# esp8266 register map
File version: 1.0
CPU: Xtensa LX106 1, little endian, no MPU, FPU, 3 interrupt priority bits
Registers are 32-bit, read-write, reset 0x0 unless marked. A register's access mark holds for its fields unless they carry their own. Offsets are from the block's base; [hi:lo] are bit positions; {n}, {i} and the like mark numbered series.

## SPI0
Base 0x60000200
Same registers: SPI1 0x60000100
0x00 SPI_CMD — In the master mode, it is the start bit of a single operation. Self-clear by hardware
  [18] spi_usr
0x04 SPI_ADDR — In the master mode, it is the value of address in "address" phase.
  [31:0] iodata_start_addr
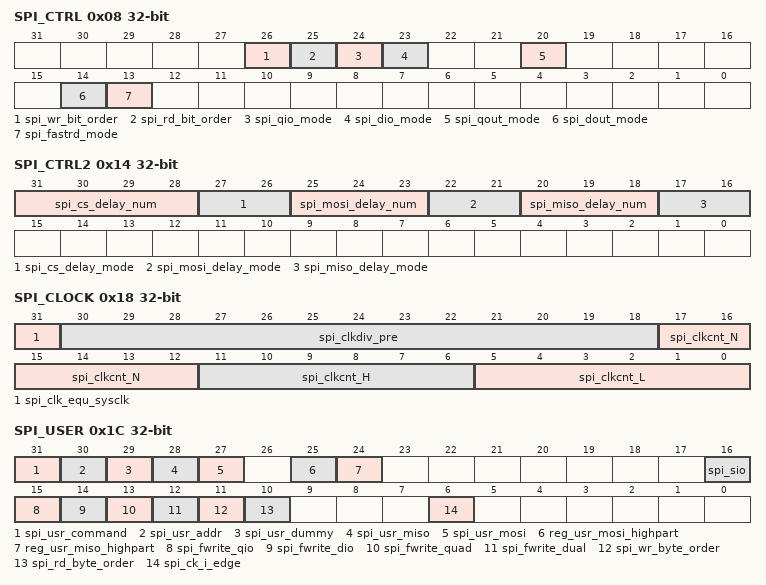
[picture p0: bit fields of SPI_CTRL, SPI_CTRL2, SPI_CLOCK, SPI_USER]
0x08 SPI_CTRL
  [26] spi_wr_bit_order — In "command", "address", "write-data" (MOSI) phases, 1: LSB first; 0: MSB first
  [25] spi_rd_bit_order — In "read-data" (MISO) phase, 1: LSB first; 0: MSB first
  [24] spi_qio_mode — In the read operations, "address" phase and "read-data" phase apply 4 signals
  [23] spi_dio_mode — In the read operations, "address" phase and "read-data" phase apply 2 signals
  [20] spi_qout_mode — In the read operations, "read-data" phase apply 4 signals
  [14] spi_dout_mode — In the read operations, "read-data" phase apply 2 signals
  [13] spi_fastrd_mode — this bit enable the bits: spi_qio_mode, spi_dio_mode, spi_qout_mode and spi_dout_mode
0x10 SPI_RD_STATUS — In the slave mode, this register are the status register for the master to read out.
  [31:0] slv_rd_status
0x14 SPI_CTRL2 — spi_cs signal is delayed by 80MHz clock cycles
  [31:28] spi_cs_delay_num — spi_cs signal is delayed by 80MHz clock cycles
  [27:26] spi_cs_delay_mode — spi_cs signal is delayed by spi_clk. 0: zero; 1: half cycle; 2: one cycle
  [25:23] spi_mosi_delay_num — MOSI signals are delayed by 80MHz clock cycles
  [22:21] spi_mosi_delay_mode — MOSI signals are delayed by spi_clk. 0: zero; 1: half cycle; 2: one cycle
  [20:18] spi_miso_delay_num — MISO signals are delayed by 80MHz clock cycles
  [17:16] spi_miso_delay_mode — MISO signals are delayed by spi_clk. 0: zero; 1: half cycle; 2: one cycle
0x18 SPI_CLOCK — In the master mode, 1: spi_clk is eqaul to 80MHz, 0: spi_clk is divided from 80 MHz clock.
  [31] spi_clk_equ_sysclk — In the master mode, 1: spi_clk is eqaul to 80MHz, 0: spi_clk is divided from 80 MHz clock.
  [30:18] spi_clkdiv_pre — In the master mode, it is pre-divider of spi_clk.
  [17:12] spi_clkcnt_N — In the master mode, it is the divider of spi_clk. So spi_clk frequency is 80MHz/(spi_clkdiv_pre+1)/(spi_clkcnt_N+1)
  [11:6] spi_clkcnt_H — In the master mode, it must be floor((spi_clkcnt_N+1)/2-1). In the slave mode, it must be 0.
  [5:0] spi_clkcnt_L — In the master mode, it must be eqaul to spi_clkcnt_N. In the slave mode, it must be 0.
0x1C SPI_USER — This bit enable the "command" phase of an operation.
  [31] spi_usr_command — This bit enable the "command" phase of an operation.
  [30] spi_usr_addr — This bit enable the "address" phase of an operation.
  [29] spi_usr_dummy — This bit enable the "dummy" phase of an operation.
  [28] spi_usr_miso — This bit enable the "read-data" phase of an operation.
  [27] spi_usr_mosi — This bit enable the "write-data" phase of an operation.
  [25] reg_usr_mosi_highpart — 1: "write-data" phase only access to high-part of the buffer spi_w8~spi_w15
  [24] reg_usr_miso_highpart — 1: "read-data" phase only access to high-part of the buffer spi_w8~spi_w15
  [16] spi_sio — 1: mosi and miso signals share the same pin
  [15] spi_fwrite_qio — In the write operations, "address" phase and "read-data" phase apply 4 signals
  [14] spi_fwrite_dio — In the write operations, "address" phase and "read-data" phase apply 2 signals
  [13] spi_fwrite_quad — In the write operations, "read-data" phase apply 4 signals
  [12] spi_fwrite_dual — In the write operations, "read-data" phase apply 2 signals
  [11] spi_wr_byte_order — In "command", "address", "write-data" (MOSI) phases, 1: little-endian; 0: big_endian
  [10] spi_rd_byte_order — In "read-data" (MISO) phase, 1: little-endian; 0: big_endian
  [6] spi_ck_i_edge — In the slave mode, 1: rising-edge; 0: falling-edge
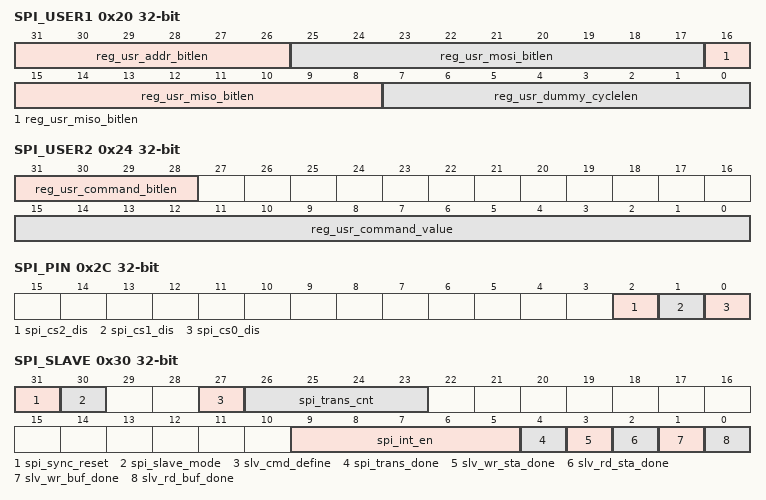
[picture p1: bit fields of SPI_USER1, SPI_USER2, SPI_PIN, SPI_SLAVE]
0x20 SPI_USER1 — The length in bits of "address" phase. The register value shall be (bit_num-1)
  [31:26] reg_usr_addr_bitlen — The length in bits of "address" phase. The register value shall be (bit_num-1)
  [25:17] reg_usr_mosi_bitlen — The length in bits of "write-data" phase. The register value shall be (bit_num-1)
  [16:8] reg_usr_miso_bitlen — The length in bits of "read-data" phase. The register value shall be (bit_num-1)
  [7:0] reg_usr_dummy_cyclelen — The length in spi_clk cycles of "dummy" phase. The register value shall be (cycle_num-1)
0x24 SPI_USER2 — The length in bits of "command" phase. The register value shall be (bit_num-1)
  [31:28] reg_usr_command_bitlen — The length in bits of "command" phase. The register value shall be (bit_num-1)
  [15:0] reg_usr_command_value — The value of "command" phase
0x28 SPI_WR_STATUS — In the slave mode, this register are the status register for the master to write into.
  [31:0] slv_wr_status
0x2C SPI_PIN — 1: disable CS2; 0: spi_cs signal is from/to CS2 pin
  [2] spi_cs2_dis — 1: disable CS2; 0: spi_cs signal is from/to CS2 pin
  [1] spi_cs1_dis — 1: disable CS1; 0: spi_cs signal is from/to CS1 pin
  [0] spi_cs0_dis — 1: disable CS0; 0: spi_cs signal is from/to CS0 pin
0x30 SPI_SLAVE access per field — It is the synchronous reset signal of the module. This bit is self-cleared by hardware.
  [31] spi_sync_reset rw — It is the synchronous reset signal of the module. This bit is self-cleared by hardware.
  [30] spi_slave_mode rw — 1: slave mode, 0: master mode.
  [27] slv_cmd_define rw — 1: slave mode commands are defined in SPI_SLAVE3. 0: slave mode commands are fixed as 1: "write-status"; 4: "read-status"; 2: "write-buffer" and 3: "read-buffer".
  [26:23] spi_trans_cnt ro — The operations counter in both the master mode and the slave mode.
  [9:5] spi_int_en rw — Interrupt enable bits for the below 5 sources
  [4] spi_trans_done rw — The interrupt raw bit for the completement of any operation in both the master mode and the slave mode.
  [3] slv_wr_sta_done rw — The interrupt raw bit for the completement of "write-status" operation in the slave mode.
  [2] slv_rd_sta_done rw — The interrupt raw bit for the completement of "read-status" operation in the slave mode.
  [1] slv_wr_buf_done rw — The interrupt raw bit for the completement of "write-buffer" operation in the slave mode.
  [0] slv_rd_buf_done rw — The interrupt raw bit for the completement of "read-buffer" operation in the slave mode.
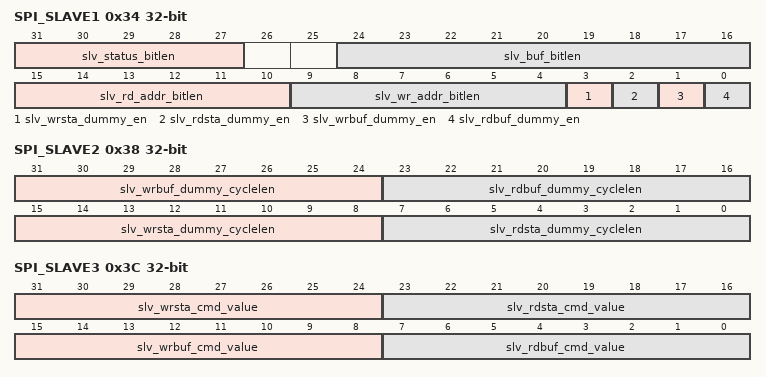
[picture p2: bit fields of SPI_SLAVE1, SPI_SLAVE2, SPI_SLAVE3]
0x34 SPI_SLAVE1 — In the slave mode, it is the length in bits for "write-status" and "read-status" operations. The register valueshall be (bit_num-1)
  [31:27] slv_status_bitlen — In the slave mode, it is the length in bits for "write-status" and "read-status" operations. The register valueshall be (bit_num-1)
  [24:16] slv_buf_bitlen — In the slave mode, it is the length in bits for "write-buffer" and "read-buffer" operations. The register value shallbe (bit_num-1)
  [15:10] slv_rd_addr_bitlen — In the slave mode, it is the address length in bits for "read-buffer" operation. The register value shall be(bit_num-1)
  [9:4] slv_wr_addr_bitlen — In the slave mode, it is the address length in bits for "write-buffer" operation. The register value shall be(bit_num-1)
  [3] slv_wrsta_dummy_en — In the slave mode, it is the enable bit of "dummy" phase for "write-status" operations.
  [2] slv_rdsta_dummy_en — In the slave mode, it is the enable bit of "dummy" phase for "read-status" operations.
  [1] slv_wrbuf_dummy_en — In the slave mode, it is the enable bit of "dummy" phase for "write-buffer" operations.
  [0] slv_rdbuf_dummy_en — In the slave mode, it is the enable bit of "dummy" phase for "read-buffer" operations.
0x38 SPI_SLAVE2 — In the slave mode, it is the length in spi_clk cycles "dummy" phase for "write-buffer" operations. The registervalue shall be (cycle_num-1)
  [31:24] slv_wrbuf_dummy_cyclelen — In the slave mode, it is the length in spi_clk cycles "dummy" phase for "write-buffer" operations. The registervalue shall be (cycle_num-1)
  [23:16] slv_rdbuf_dummy_cyclelen — In the slave mode, it is the length in spi_clk cycles of "dummy" phase for "read-buffer" operations. The registervalue shall be (cycle_num-1)
  [15:8] slv_wrsta_dummy_cyclelen — In the slave mode, it is the length in spi_clk cycles of "dummy" phase for "write-status" operations. Theregister value shall be (cycle_num-1)
  [7:0] slv_rdsta_dummy_cyclelen — In the slave mode, it is the length in spi_clk cycles of "dummy" phase for "read-status" operations. Theregister value shall be (cycle_num-1)
0x3C SPI_SLAVE3 — In slave mode, it is the value of "write-status" command
  [31:24] slv_wrsta_cmd_value — In slave mode, it is the value of "write-status" command
  [23:16] slv_rdsta_cmd_value — In slave mode, it is the value of "read-status" command
  [15:8] slv_wrbuf_cmd_value — In slave mode, it is the value of "write-buffer" command
  [7:0] slv_rdbuf_cmd_value — In slave mode, it is the value of "read-buffer" command
{0x40+0x20*i} SPI_W{i} (i=0..15) — the data inside the buffer of the SPI module, byte {i}
0xFC SPI_EXT3 — This register is for two SPI masters to share the same cs, clock and data signals.
  [1:0] reg_int_hold_ena
